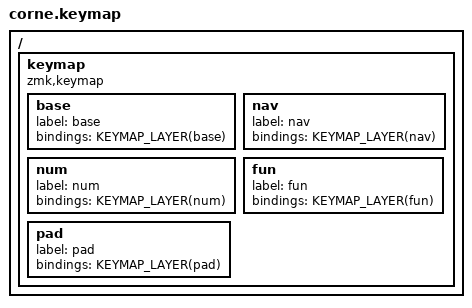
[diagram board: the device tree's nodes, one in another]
/*
 * Corne (corne_ul) — thin keymap. Standard foostan Corne 3x6+3 split, using the
 * corne_left/corne_right shields built into ZMK core (no external module/vendoring).
 * First superset board: the outer pinky column and 3rd (outer) thumb map to the
 * master's optional OUT/TH_O slots, which are currently reserved (inactive) — the
 * board runs the canonical 34-key core. All content lives in config/shared/.
 */

#include <behaviors.dtsi>
#include <dt-bindings/zmk/keys.h>
#include <dt-bindings/zmk/bt.h>
#include <dt-bindings/zmk/outputs.h>

#include "geometry/geom_corne.h"

#include "shared/keys_de.h"
#include "shared/settings.dtsi"
#include "shared/behaviors.dtsi"
#include "shared/macros.dtsi"
#include "shared/combos.dtsi"
#include "shared/core_blocks.dtsi"

/ {
    keymap {
        compatible = "zmk,keymap";

        base { label = "base"; bindings = <KEYMAP_LAYER(base)>; };
        nav  { label = "nav";  bindings = <KEYMAP_LAYER(nav)>;  };
        num  { label = "num";  bindings = <KEYMAP_LAYER(num)>;  };
        fun  { label = "fun";  bindings = <KEYMAP_LAYER(fun)>;  };
        pad  { label = "pad";  bindings = <KEYMAP_LAYER(pad)>;  };
    };
};
